# GD32A72_A74x register map
File version: 1.0
CPU: CM7 r2p1, little endian, MPU, FPU, DSP, 4 interrupt priority bits
Registers are 32-bit, read-write, reset 0x0 unless marked. A register's access mark holds for its fields unless they carry their own. Offsets are from the block's base; [hi:lo] are bit positions; 'fields as' and 'values as' point back to an identical list.

## ENET_MTL
Base 0x4000AC00
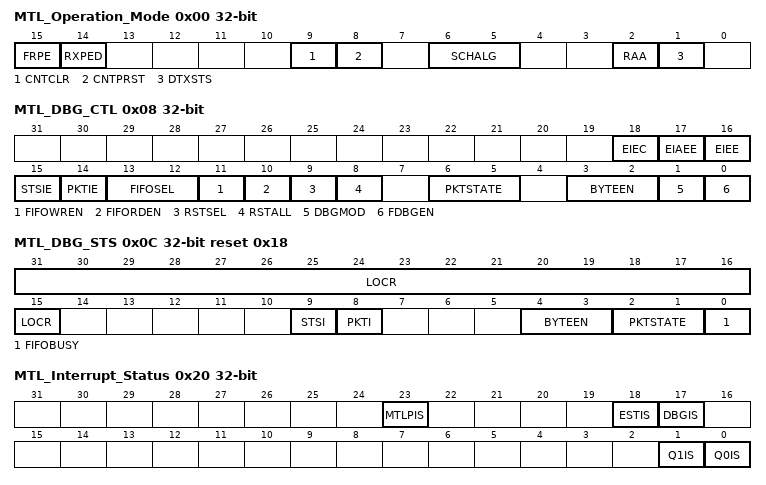
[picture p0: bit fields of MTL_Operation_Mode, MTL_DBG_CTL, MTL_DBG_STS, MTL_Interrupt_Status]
0x00 MTL_Operation_Mode
  [15] FRPE — Flexible Receive Parser Enable
    0=DISABLE (Disabled); 1=ENABLE (Enabled)
  [14] RXPED — RxParser Software Error/Incomplete Parsing Packet Drop Enable
    0=DISABLE (Not reset); 1=ENABLE (Reset)
  [9] CNTCLR — Counters Reset
    0=DISABLE (Not reset); 1=ENABLE (Reset)
  [8] CNTPRST — Counters Preset
    0=DISABLE (Disabled); 1=ENABLE (Enabled)
  [6:5] SCHALG — Transmit Scheduling Algorithm
    0=WRR (WRR algorithm); 1=WFQ (WFQ algorithm when DCB feature selected; otherwise, reserved); 2=DWRR (DWRR algorithm when DCB feature selected; otherwise, reserved); 3=SP (Strict priority algorithm)
  [2] RAA — Receive Arbitration Algorithm
    0=SP (Strict priority (SP)); 1=WSP (Weighted strict priority (WSP))
  [1] DTXSTS — Drop Transmit Status
    0=DISABLE (Disabled); 1=ENABLE (Enabled)
0x08 MTL_DBG_CTL — MTL Debug Control
  [18] EIEC — ECC Inject Error Control for Tx, Rx memories
  [17] EIAEE — ECC Inject Address Error for Tx, Rx memories
  [16] EIEE — ECC Inject Error Enable
    0=DISABLE (Disabled); 1=ENABLE (Enabled)
  [15] STSIE — Transmit Status Available Interrupt Status Enable
    0=DISABLE (Disabled); 1=ENABLE (Enabled)
  [14] PKTIE — Receive Packet Available Interrupt Status Enable
    0=DISABLE (Disabled); 1=ENABLE (Enabled)
  [13:12] FIFOSEL — FIFO Selected for Access
    0=TXFIFO (Transmit FIFO); 1=TXSTSFIFO (Transmit status FIFO (only read access when SLVMOD is set)); 2=TSOFIFO (TSO FIFO (cannot be accessed when SLVMOD is set)); 3=RXFIFO (Receive FIFO)
  [11] FIFOWREN — FIFO Write Enable
    0=DISABLE (Disabled); 1=ENABLE (Enabled)
  [10] FIFORDEN — FIFO Read Enable
    0=DISABLE (Disabled); 1=ENABLE (Enabled)
  [9] RSTSEL — Reset Pointers Of Selected FIFO
    0=DISABLE (Disabled); 1=ENABLE (Enabled)
  [8] RSTALL — Reset All Pointers
    0=DISABLE (Disabled); 1=ENABLE (Enabled)
  [6:5] PKTSTATE — Encoded Packet State
    0=PKT_DATA (Packet data); 1=CW_NS (Control word/normal status); 2=SOP_LS (SOP data/last status); 3=EOP (EOP data/EOP)
  [3:2] BYTEEN — Byte Enables
    0=B0_VAL (Byte 0 valid); 1=B01_VAL (Byte 0 and byte 1 valid); 2=B012_VAL (Byte 0, byte 1, and byte 2 valid); 3=B0123_VAL (All four bytes valid)
  [1] DBGMOD — Debug Mode Access to FIFO
    0=DISABLE (Disabled); 1=ENABLE (Enabled)
  [0] FDBGEN — FIFO Debug Access Enable
    0=DISABLE (Disabled); 1=ENABLE (Enabled)
0x0C MTL_DBG_STS reset 0x18 — MTL Debug Status
  [31:15] LOCR ro — Remaining Locations In FIFO
  [9] STSI — Transmit Status Available Interrupt Status
    0=INACTIVE (Not detected); 1=ACTIVE (Detected)
  [8] PKTI — Receive Packet Available Interrupt Status
    0=INACTIVE (Not detected); 1=ACTIVE (Detected)
  [4:3] BYTEEN ro — Byte Enables
    values as MTL_DBG_CTL.BYTEEN
  [2:1] PKTSTATE ro — Encoded Packet State
    values as MTL_DBG_CTL.PKTSTATE
  [0] FIFOBUSY ro
    0=INACTIVE (Not detected); 1=ACTIVE (Detected)
0x10 MTL_FIFO_Debug_Data
  [31:0] FDBGDATA — FIFO Debug Data
0x20 MTL_Interrupt_Status ro
  [all] fields
    0=INACTIVE (Not detected); 1=ACTIVE (Detected)
  [23] MTLPIS — MTL Receive Parser Interrupt Status
  [18] ESTIS — EST (TAS- 802.1Qbv) Interrupt Status
  [17] DBGIS — Debug Interrupt Status
  [1] Q1IS — Queue 1 Interrupt Status
  [0] Q0IS — Queue 0 Interrupt Status
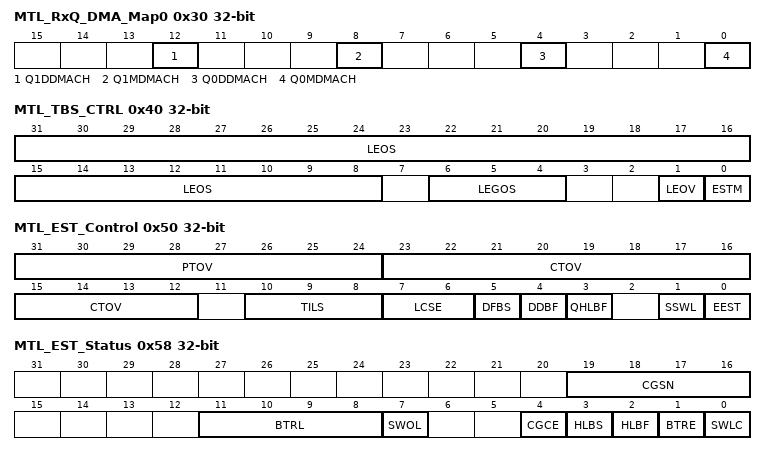
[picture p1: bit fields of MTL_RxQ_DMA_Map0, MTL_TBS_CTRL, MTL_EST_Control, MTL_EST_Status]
0x30 MTL_RxQ_DMA_Map0 — MTL Receive Queue DMA Map 0
  [12] Q1DDMACH — Queue 1 Enabled for DA-based DMA Channel Selection
    0=DISABLE (Disabled); 1=ENABLE (Enabled)
  [8] Q1MDMACH — Queue 1 Mapped to DMA Channel
  [4] Q0DDMACH — Queue 0 Enabled for DA-based DMA Channel Selection
    0=DISABLE; 1=ENABLE
  [0] Q0MDMACH — Queue 0 Mapped to DMA Channel
0x40 MTL_TBS_CTRL — MTL TBS Control
  [31:8] LEOS — Launch Expiry Offset
  [6:4] LEGOS — Launch Expiry GSN Offset
  [1] LEOV — Launch Expiry Offset Valid
    0=INVALID; 1=VALID
  [0] ESTM — EST offset Mode
    0=DISABLE (Disabled); 1=ENABLE (Enabled)
0x50 MTL_EST_Control
  [31:24] PTOV — PTP Time Offset Value
  [23:12] CTOV — Current Time Offset Value
  [10:8] TILS — Time Interval Left Shift Amount
  [7:6] LCSE — Loop Count to Report Scheduling Error
    0=M_4_ITERNS (4 iterations); 1=M_8_ITERNS (8 iterations); 2=M_16_ITERNS (16 iterations); 3=M_32_ITERNS (32 iterations)
  [5] DFBS — Drop Frames Causing Scheduling Error
    0=DONT_DROP (Do not drop frames); 1=DROP (Drop frames)
  [4] DDBF — Do not Drop Frames during Frame Size Error
    0=DROP (Drop frames during frame size error); 1=DONT_DROP (Do not Drop frames during frame size error)
  [3] QHLBF — Quick Assertion of HLBF Error
  [1] SSWL — Switch to Software Owned List
    0=DISABLE (Disabled); 1=ENABLE (Enabled)
  [0] EEST — Enable EST
    0=DISABLE (Disabled); 1=ENABLE (Enabled)
0x54 MTL_EST_Ext_Control — MTL EST extend control register
  [5:0] OVHD — Overhead Bytes Value
0x58 MTL_EST_Status
  [19:16] CGSN ro — Current GCL Slot Number Indicates the slot number of the GCL list
  [11:8] BTRL ro — BTR Error Loop Count Provides the minimum count (N) for which the equation Current Time =< New BTR + (N * New Cycle Time) becomes true
  [7] SWOL ro — S/W owned list When '0' indicates Gate control list number "0" is owned by software and when "1" indicates the Gate Control list "1" is owned by the software
    0=INACTIVE (Gate control list number "0" is owned by software); 1=ACTIVE (Gate control list number "1" is owned by software)
  [4] CGCE — Constant Gate Control Error This error occurs when the list length (LLR) is 1 and the Cycle Time (CTR) is less than or equal to the programmed Time Interval (TI) value after the optional Left Shifting
    0=INACTIVE (Constant Gate Control Error not detected); 1=ACTIVE (Constant Gate Control Error detected)
  [3] HLBS ro — Head-Of-Line Blocking due to Scheduling Set when the frame is not able to win arbitration and get scheduled even after 4 iterations of the GCL
    0=INACTIVE (Head-Of-Line Blocking due to Scheduling not detected); 1=ACTIVE (Head-Of-Line Blocking due to Scheduling detected)
  [2] HLBF ro — Head-Of-Line Blocking due to Frame Size Set when HOL Blocking is noticed on one or more Queues as a result of none of the Time Intervals of gate open in the GCL being greater than or equal to the duration needed for frame size (or frame fragment size when preemption is enabled) transmission
    0=INACTIVE (Head-Of-Line Blocking due to Frame Size not detected); 1=ACTIVE (Head-Of-Line Blocking due to Frame Size detected)
  [1] BTRE — BTR Error
    0=INACTIVE (BTR Error not detected); 1=ACTIVE (BTR Error detected)
  [0] SWLC — Switch to Software Owned List Complete
    0=INACTIVE (Not detected); 1=ACTIVE (Detected)
0x60 MTL_EST_Sch_Error — MTL EST Scheduling Error
  [1:0] SEQN — Schedule Error Queue Number
0x64 MTL_EST_Frm_Size_Error — MTL EST Frame Size Error
  [1:0] FEQN — Frame Size Error Queue Number
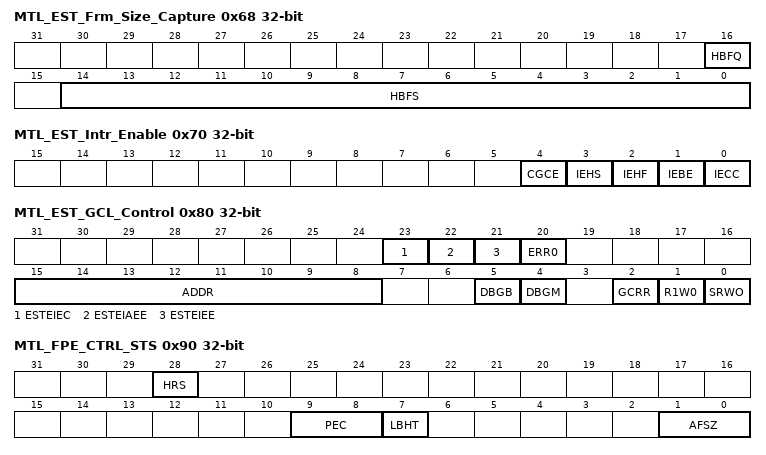
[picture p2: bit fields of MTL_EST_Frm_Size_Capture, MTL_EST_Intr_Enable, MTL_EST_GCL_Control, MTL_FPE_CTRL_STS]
0x68 MTL_EST_Frm_Size_Capture ro — MTL EST Frame Size Capture
  [16] HBFQ — Queue Number of HLBF
  [14:0] HBFS — Frame Size of HLBF
0x70 MTL_EST_Intr_Enable — MTL EST Interrupt Enable
  [all] fields
    0=DISABLE (Disabled); 1=ENABLE (Enabled)
  [4] CGCE — Interrupt Enable for CGCE
  [3] IEHS — Interrupt Enable for HLBS
  [2] IEHF — Interrupt Enable for HLBF
  [1] IEBE — Interrupt Enable for BTR Error
  [0] IECC — Interrupt Enable for Switch List
0x80 MTL_EST_GCL_Control
  [23] ESTEIEC — ECC Inject Error Control for EST Memory
  [22] ESTEIAEE — EST ECC Inject Address Error Enable
  [21] ESTEIEE — EST ECC Inject Error Enable
    0=DISABLE (Disabled); 1=ENABLE (Enabled)
  [20] ERR0 — If this field is 1, it indicates that when the software writes to GCL the last write operation was aborted and when MTL_EST_Control[SSWL] is 1, GCL registers are prohibited
    0=DISABLE (ERR0 is disabled); 1=ENABLE (ERR1 is enabled)
  [15:8] ADDR — Gate Control List Address: (GCLA when GCRR is "0")
  [5] DBGB — Debug Mode Bank Select
    0=BANK0 (Directed to bank 0); 1=BANK1 (Directed to bank 1)
  [4] DBGM — Debug Mode
    0=DISABLE (Disabled); 1=ENABLE (Enabled)
  [2] GCRR — Gate Control Related Registers
    0=DISABLE (Disabled); 1=ENABLE (Enabled)
  [1] R1W0 — Read '1', Write '0'
    0=WRITE (Write operation); 1=READ (Read operation)
  [0] SRWO — Start Read/Write Operation
    0=DISABLE (Disabled); 1=ENABLE (Enabled)
0x84 MTL_EST_GCL_Data
  [31:0] GCD — Gate Control Data
0x90 MTL_FPE_CTRL_STS — MTL FPE Control Status
  [28] HRS ro — Hold/Release Status
    0=SET_REL (Release state); 1=SET_HOLD (Hold state)
  [9:8] PEC — Preemption Classification
  [7] LBHT — Level Based Hold Transition
  [1:0] AFSZ — Additional Fragment Size
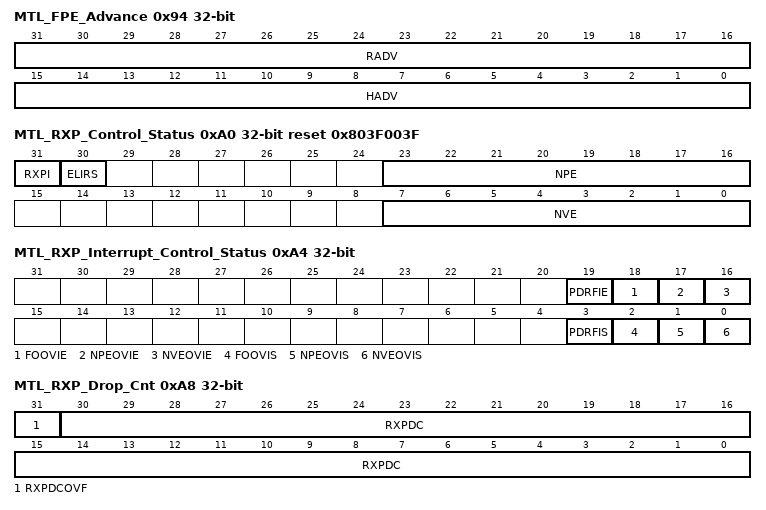
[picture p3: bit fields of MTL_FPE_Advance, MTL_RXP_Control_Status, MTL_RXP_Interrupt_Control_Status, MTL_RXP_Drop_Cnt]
0x94 MTL_FPE_Advance
  [31:16] RADV — Release Advance
  [15:0] HADV — Hold Advance
0xA0 MTL_RXP_Control_Status reset 0x803F003F — MTL Rx Parser Control Status
  [31] RXPI ro — RX Parser in Idle State
    0=INACTIVE (Not in Idle state); 1=ACTIVE (Idle state)
  [30] ELIRS — Enable Last Instruction in RX Status
  [23:16] NPE — Number of parsable entries in the Instruction table
  [7:0] NVE — Number Of Valid Entry Address Or Index In The Instruction Table
0xA4 MTL_RXP_Interrupt_Control_Status — MTL Rx Parser Interrupt Control Status
  [19] PDRFIE — Packet Drop due to RF Interrupt Enable
    0=DISABLE (Disabled); 1=ENABLE (Enabled)
  [18] FOOVIE — Frame Offset Overflow Interrupt Enable
    0=DISABLE (Disabled); 1=ENABLE (Enabled)
  [17] NPEOVIE — Number of Parsable Entries Overflow Interrupt Enable
    0=DISABLE; 1=ENABLE
  [16] NVEOVIE — Number of Valid Entries Overflow Interrupt Enable
    0=DISABLE; 1=ENABLE
  [3] PDRFIS — Packet Dropped due to RF Interrupt Status
    0=INACTIVE (Not detected); 1=ACTIVE (Detected)
  [2] FOOVIS — Frame Offset Overflow Interrupt Status
    0=INACTIVE (Not detected); 1=ACTIVE (Detected)
  [1] NPEOVIS — Number of Parsable Entries Overflow Interrupt Status
    0=INACTIVE (Not detected); 1=ACTIVE (Detected)
  [0] NVEOVIS — Number of Valid Entry Address/Index Overflow Interrupt Status
    0=INACTIVE (Not detected); 1=ACTIVE (Detected)
0xA8 MTL_RXP_Drop_Cnt ro — MTL Rx Parser Drop Count
  [31] RXPDCOVF — Rx Parser Drop Counter Overflow Bit
    0=INACTIVE (Not occurred); 1=ACTIVE (Occurred)
  [30:0] RXPDC — Rx Parser Drop Count
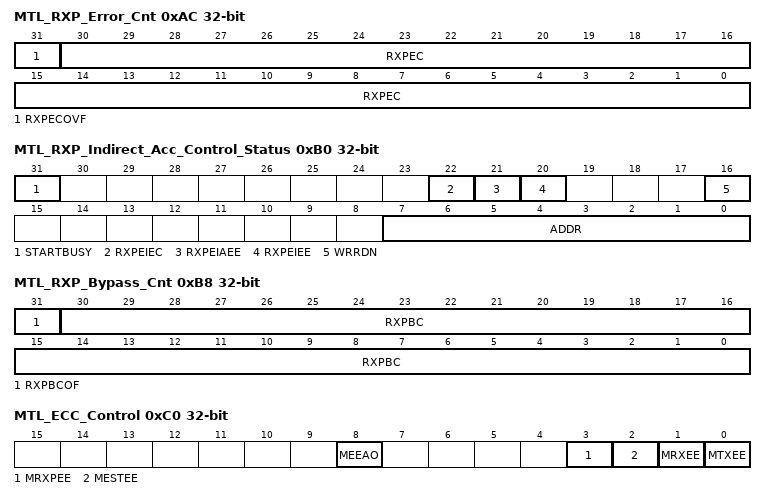
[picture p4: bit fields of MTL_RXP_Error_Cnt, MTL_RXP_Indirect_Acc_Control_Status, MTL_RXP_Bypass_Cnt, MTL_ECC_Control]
0xAC MTL_RXP_Error_Cnt ro — MTL Rx Parser Error Count
  [31] RXPECOVF — Rx Parser Error Counter Overflow Bit
    0=INACTIVE (Not occurred); 1=ACTIVE (Occurred)
  [30:0] RXPEC — Rx Parser Error Count
0xB0 MTL_RXP_Indirect_Acc_Control_Status — MTL Rx Parser Indirect Access Control Status
  [31] STARTBUSY — FRP Instruction Table Access Busy
    0=INACTIVE (hardware not busy); 1=ACTIVE (hardware is busy (Read/Write operation from/to the Rx Parser Memory))
  [22] RXPEIEC — ECC Inject Error Control for Rx Parser Memory
  [21] RXPEIAEE — ECC Inject Address Error Enable for Rx Parser Memory
  [20] RXPEIEE — ECC Inject Error Enable for Rx Parser Memory
    0=DISABLE (Disabled); 1=ENABLE (Enabled)
  [16] WRRDN — Read Write Control
    0=READ (Read operation to the receive parser memory); 1=WRITE (Write operation to the receive parser memory)
  [7:0] ADDR — FRP Instruction Table Offset Address
0xB4 MTL_RXP_Indirect_Acc_Data ro — MTL Rx Parser Indirect Access Data
  [31:0] DATA — FRP Instruction Table Write/Read Data
0xB8 MTL_RXP_Bypass_Cnt ro — MTL Rx parser bypass counter register
  [31] RXPBCOF — Rx Parser Bypass Counter Overflow Bit
  [30:0] RXPBC — Rx Parser Bypass count
0xC0 MTL_ECC_Control
  [8] MEEAO — MTL ECC Error Address Status Over-ride
    0=DISABLE; 1=ENABLE
  [3] MRXPEE — MTL Rx Parser ECC Enable
    0=DISABLE (Disabled); 1=ENABLE (Enabled)
  [2] MESTEE — MTL EST ECC Enable
    0=DISABLE (Disabled); 1=ENABLE (Enabled)
  [1] MRXEE — MTL Rx FIFO ECC Enable
    0=DISABLE (Disabled); 1=ENABLE (Enabled)
  [0] MTXEE — MTL Tx FIFO ECC Enable
    0=DISABLE (Disabled); 1=ENABLE (Enabled)
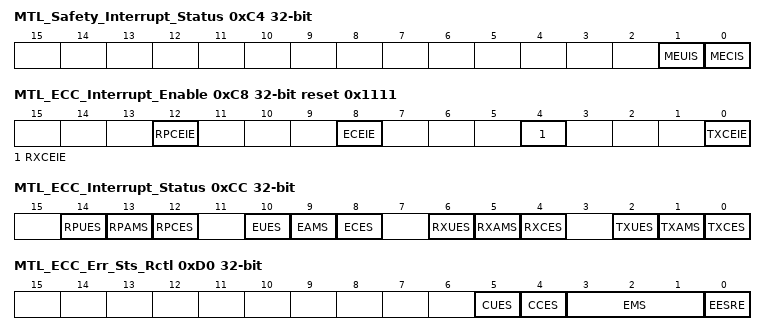
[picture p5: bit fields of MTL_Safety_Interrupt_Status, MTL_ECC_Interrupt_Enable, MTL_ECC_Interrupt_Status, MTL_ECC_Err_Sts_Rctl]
0xC4 MTL_Safety_Interrupt_Status ro — MTL Safety Interript Status
  [1] MEUIS — MTL ECC Uncorrectable Error Interrupt Status
    0=INACTIVE (Not detected); 1=ACTIVE (Detected)
  [0] MECIS — MTL ECC Correctable Error Interrupt Status
    0=INACTIVE (MTL ECC Correctable error Interrupt Status not detected); 1=ACTIVE (MTL ECC Correctable error Interrupt Status detected)
0xC8 MTL_ECC_Interrupt_Enable reset 0x1111
  [all] fields
    0=DISABLE (Disabled); 1=ENABLE (Enabled)
  [12] RPCEIE — Rx Parser Memory Correctable Error Interrupt Enable
  [8] ECEIE — EST Memory Correctable Error Interrupt Enable
  [4] RXCEIE — Rx Memory Correctable Error Interrupt Enable
  [0] TXCEIE — Tx Memory Correctable Error Interrupt Enable
0xCC MTL_ECC_Interrupt_Status
  [all] fields
    0=INACTIVE (Not detected); 1=ACTIVE (Detected)
  [14] RPUES — Rx Parser Memory Uncorrectable Error Status
  [13] RPAMS — MTL Rx Parser Memory Address Mismatch Status
  [12] RPCES — MTL Rx Parser Memory Correctable Error Status
  [10] EUES — MTL EST Memory Uncorrectable Error Status
  [9] EAMS — MTL EST Memory Address Mismatch Status
  [8] ECES — MTL EST Memory Correctable Error Status
  [6] RXUES — MTL Rx Memory Uncorrectable Error Status
  [5] RXAMS — MTL Rx Memory Address Mismatch Status
  [4] RXCES — MTL Rx memory Correctable Error Status
  [2] TXUES — MTL Tx Memory Uncorrectable Error Status
  [1] TXAMS — MTL Tx Memory Address Mismatch Status
  [0] TXCES — MTL Tx Memory Correctable Error Status
0xD0 MTL_ECC_Err_Sts_Rctl — MTL ECC Error Status
  [5] CUES — Clear Uncorrectable Error Status
    0=INACTIVE (Not detected); 1=ACTIVE (Detected)
  [4] CCES — Clear Correctable Error Status
    0=INACTIVE (Not detected); 1=ACTIVE (Detected)
  [3:1] EMS — MTL ECC Memory Selection
    0=TX_MEM (MTL Tx memory); 1=RX_MEM (MTL Rx memory); 2=EST_MEM (MTL EST memory); 3=RXP_MEM (MTL Rx Parser memory); 4=TSO_MEM (DMA TSO memory)
  [0] EESRE — MTL ECC Error Status Read Enable
    0=DISABLE (Disabled); 1=ENABLE (Enabled)
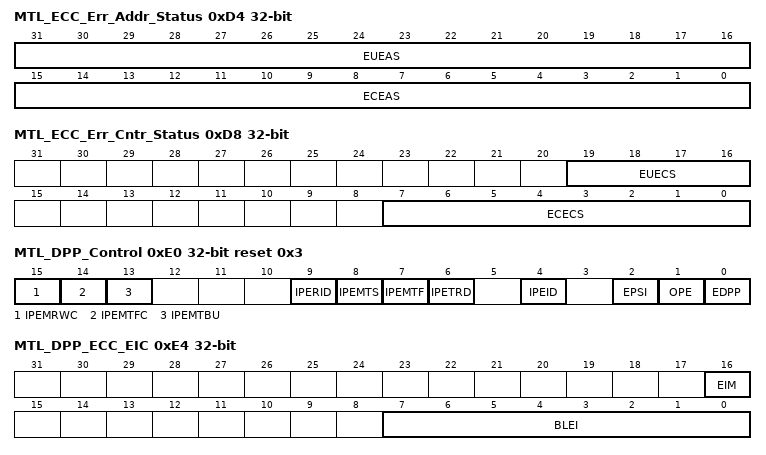
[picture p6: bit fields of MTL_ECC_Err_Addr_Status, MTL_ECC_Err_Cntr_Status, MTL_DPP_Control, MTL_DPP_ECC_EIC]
0xD4 MTL_ECC_Err_Addr_Status ro — MTL ECC Error Adress Status
  [31:16] EUEAS — MTL ECC Uncorrectable Error Address Status
  [15:0] ECEAS — MTL ECC Correctable Error Address Status
0xD8 MTL_ECC_Err_Cntr_Status ro — MTL ECC Error Control Status
  [19:16] EUECS — MTL ECC Uncorrectable Error Counter Status Based on the EMS field of MTL_ECC_Err_Cntr_Rctl register, this field holds the respective memory's uncorrectable error count value
  [7:0] ECECS — MTL ECC Correctable Error Counter Status Based on the EMS field of MTL_ECC_Err_Cntr_Rctl register, this field holds the respective memory's correctable error count value
0xE0 MTL_DPP_Control reset 0x3
  [15] IPEMRWC — Insert Parity error in MTL RWC data Parity Checker
    0=DISABLE (Disabled); 1=ENABLE (Enabled)
  [14] IPEMTFC — Insert Parity error in MAC TFC data Parity Checker
    0=DISABLE (Disabled); 1=ENABLE (Enabled)
  [13] IPEMTBU — Insert Parity error in MAC TBU data Parity Checker
    0=DISABLE (Disabled); 1=ENABLE (Enabled)
  [9] IPERID — Insert Parity Error in RX Interface Data Parity Checker
    0=DISABLE (Disabled); 1=ENABLE (Enabled)
  [8] IPEMTS — Insert Parity Error in MTL Tx Status FIFO Parity Checker
    0=DISABLE (Disabled); 1=ENABLE (Enabled)
  [7] IPEMTF — Insert Parity Error in MTL Tx FIFO write data Parity Checker
    0=DISABLE (Disabled); 1=ENABLE (Enabled)
  [6] IPETRD — Insert Parity Error in DMA Tx/Rx Descriptor Parity Checker
    0=DISABLE (Disabled); 1=ENABLE (Enabled)
  [4] IPEID — Insert Parity Error in Interface Data Parity Generator
    0=DISABLE (Disabled); 1=ENABLE (Enabled)
  [2] EPSI ro — Enable Parity on Slave Interface port
  [1] OPE ro — Odd Parity Enable
    0=DISABLE (Disabled); 1=ENABLE (Enabled)
  [0] EDPP — Enable Data path Parity Protection
    0=DISABLE; 1=ENABLE
0xE4 MTL_DPP_ECC_EIC — MTL ECC/DPP error injection register
  [16] EIM — Error Injection Mode
  [7:0] BLEI — Bit Location of error injection
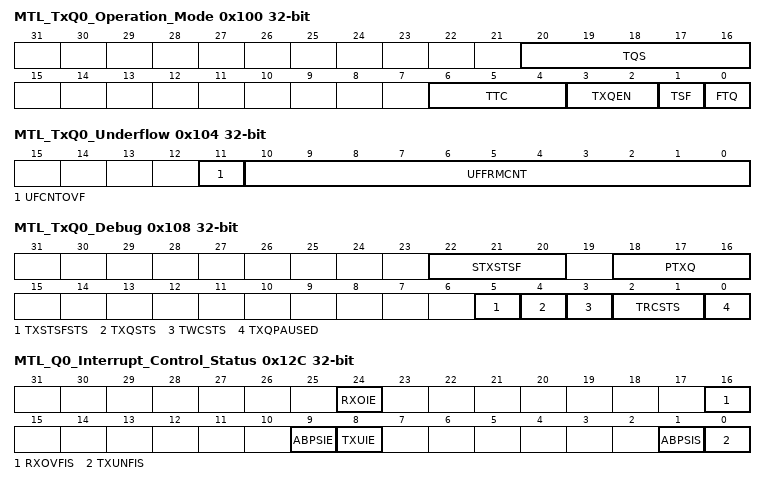
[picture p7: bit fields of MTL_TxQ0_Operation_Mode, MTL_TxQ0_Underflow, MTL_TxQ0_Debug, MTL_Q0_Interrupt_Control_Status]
0x100 MTL_TxQ0_Operation_Mode — MTL Tx Queue 0 Operation Mode
  [20:16] TQS — Transmit Queue Size
  [6:4] TTC — Transmit Threshold Control
    0=M_32BYTES (32); 1=M_64BYTES (64); 2=M_96BYTES (96); 3=M_128BYTES (128); 4=M_192BYTES (192); 5=M_256BYTES (256); 6=M_384BYTES (384); 7=M_512BYTES (512)
  [3:2] TXQEN — Transmit Queue Enable
    0=DISABLE (Not enabled); 1=EN_IF_AV (Enable in AV mode (Reserved in non-AV)); 2=ENABLE (Enabled)
  [1] TSF — Transmit Store and Forward
    0=DISABLE (Disabled); 1=ENABLE (Enabled)
  [0] FTQ — Flush Transmit Queue
    0=DISABLE (Disabled); 1=ENABLE (Enabled)
0x104 MTL_TxQ0_Underflow ro — MTL Tx Queue 0 Underflow
  [11] UFCNTOVF — Overflow Bit for Underflow Packet Counter
    0=INACTIVE (Not detected); 1=ACTIVE (Detected)
  [10:0] UFFRMCNT — Underflow Packet Counter
0x108 MTL_TxQ0_Debug ro — MTL Tx Queue 0 Debug
  [22:20] STXSTSF — Number of Status Words in Tx Status FIFO of Queue
  [18:16] PTXQ — Number of Packets in the Transmit Queue
  [5] TXSTSFSTS — MTL Tx Status FIFO Full Status
    0=INACTIVE (Not detected); 1=ACTIVE (Detected)
  [4] TXQSTS — MTL Tx Queue Not Empty Status
    0=INACTIVE (Not detected); 1=ACTIVE (Detected)
  [3] TWCSTS — MTL Tx Queue Write Controller Status
    0=INACTIVE (Not detected); 1=ACTIVE (Detected)
  [2:1] TRCSTS — MTL Tx Queue Read Controller Status
    0=IDLE (Idle state); 1=READ (Read state (transferring data to the MAC transmitter)); 2=WAIT (Waiting for pending transit status from the MAC transmitter); 3=FLUSH (Flushing the transit queue because of the packet abort request from the MAC)
  [0] TXQPAUSED — Transmit Queue in Pause
    0=INACTIVE (Not detected); 1=ACTIVE (Detected)
0x114 MTL_TxQ0_ETS_Status ro — MTL Tx Queue 0 ETS Status
  [23:0] ABS — Average Bits per Slot
0x118 MTL_TxQ0_Quantum_Weight — MTL Tx Queue Quantum Weight
  [20:0] ISCQW — Quantum or Weights
0x12C MTL_Q0_Interrupt_Control_Status — MTL Queue 0 Interrupt Control Status
  [24] RXOIE — Receive Queue Overflow Interrupt Enable
    0=DISABLE (Disabled); 1=ENABLE (Enabled)
  [16] RXOVFIS — Receive Queue Overflow Interrupt Status
    0=INACTIVE (Not detected); 1=ACTIVE (Detected)
  [9] ABPSIE — Average Bits Per Slot Interrupt Enable
    0=DISABLE (Disabled); 1=ENABLE (Enabled)
  [8] TXUIE — Transmit Queue Underflow Interrupt Enable
    0=DISABLE (Disabled); 1=ENABLE (Enabled)
  [1] ABPSIS — Average Bits Per Slot Interrupt Status
    0=INACTIVE (Not detected); 1=ACTIVE (Detected)
  [0] TXUNFIS — Transmit Queue Underflow Interrupt Status
    0=INACTIVE (Not detected); 1=ACTIVE (Detected)
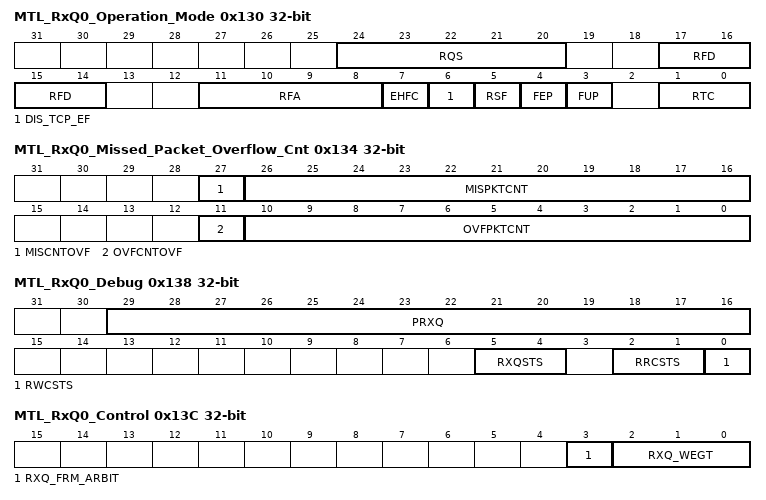
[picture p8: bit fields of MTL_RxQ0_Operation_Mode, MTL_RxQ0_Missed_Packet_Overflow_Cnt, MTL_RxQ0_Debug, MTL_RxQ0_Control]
0x130 MTL_RxQ0_Operation_Mode — MTL Rx Queue 0 Operation Mode
  [24:20] RQS — Receive Queue Size
  [17:14] RFD — Threshold for Deactivating Flow Control (in half-duplex and full-duplex modes)
  [11:8] RFA — Threshold for Activating Flow Control (in half-duplex and full-duplex)
  [7] EHFC — Enable Hardware Flow Control
    0=DISABLE; 1=ENABLE
  [6] DIS_TCP_EF — Disable Dropping of TCP/IP Checksum Error Packets
    0=ENABLE; 1=DISABLE
  [5] RSF — Receive Queue Store and Forward
    0=DISABLE (Disabled); 1=ENABLE (Enabled)
  [4] FEP — Forward Error Packets
    0=DISABLE (Disabled); 1=ENABLE (Enabled)
  [3] FUP — Forward Undersized Good Packets
    0=DISABLE (Disabled); 1=ENABLE (Enabled)
  [1:0] RTC — Receive Queue Threshold Control
    0=M_64BYTE (64); 1=M_32BYTE (32); 2=M_96BYTE (96); 3=M_128BYTE (128)
0x134 MTL_RxQ0_Missed_Packet_Overflow_Cnt ro — MTL Rx Queue Missed Packet Overflow Count
  [27] MISCNTOVF — Missed Packet Counter Overflow Bit
    0=INACTIVE (Not detected); 1=ACTIVE (Detected)
  [26:16] MISPKTCNT — Missed Packet Counter
  [11] OVFCNTOVF — Overflow Counter Overflow Bit
    0=INACTIVE (Not detected); 1=ACTIVE (Detected)
  [10:0] OVFPKTCNT — Overflow Packet Counter
0x138 MTL_RxQ0_Debug ro — MTL Rx Queue 0 Debug
  [29:16] PRXQ — Number of Packets in Receive Queue
  [5:4] RXQSTS — MTL Rx Queue Fill-Level Status
    0=EMPTY (Rx Queue empty); 1=BLW_THR (Rx Queue fill-level below flow-control deactivate threshold); 2=ABV_THR (Rx Queue fill-level above flow-control activate threshold); 3=FULL (Rx Queue full)
  [2:1] RRCSTS — MTL Rx Queue Read Controller State
    0=IDLE (Idle state); 1=READ_DATA (Reading packet data); 2=READ_STS (Reading packet status (or timestamp)); 3=FLUSH (Flushing the packet data and status)
  [0] RWCSTS — MTL Rx Queue Write Controller Active Status
    0=INACTIVE (Not detected); 1=ACTIVE (Detected)
0x13C MTL_RxQ0_Control — MTL Rx Queue 0 Control 0
  [3] RXQ_FRM_ARBIT — Receive Queue Packet Arbitration
    0=DISABLE (Disabled); 1=ENABLE (Enabled)
  [2:0] RXQ_WEGT — Receive Queue Weight
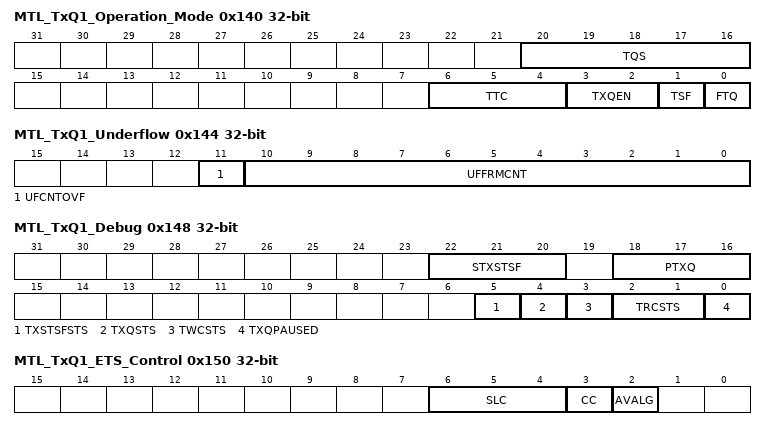
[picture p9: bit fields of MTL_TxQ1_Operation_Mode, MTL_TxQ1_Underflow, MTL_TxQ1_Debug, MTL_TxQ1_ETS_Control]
0x140 MTL_TxQ1_Operation_Mode — MTL Tx Queue 1 Operation Mode
  [20:16] TQS — Transmit Queue Size
  [6:4] TTC — Transmit Threshold Control
    values as MTL_TxQ0_Operation_Mode.TTC
  [3:2] TXQEN — Transmit Queue Enable
    values as MTL_TxQ0_Operation_Mode.TXQEN
  [1] TSF — Transmit Store and Forward
    0=DISABLE (Transmit Store and Forward is disabled); 1=ENABLE (Transmit Store and Forward is enabled)
  [0] FTQ — Flush Transmit Queue
    0=DISABLE (Disabled); 1=ENABLE (Enabled)
0x144 MTL_TxQ1_Underflow ro — MTL Tx Queue 1 Underflow
  fields as MTL_TxQ0_Underflow
0x148 MTL_TxQ1_Debug ro — MTL Tx Queue 1 Debug
  fields as MTL_TxQ0_Debug
0x150 MTL_TxQ1_ETS_Control — MTL Tx Queue 1 ETS Control
  [6:4] SLC — Slot Count
    0=M_1_SLOT (1 slot); 1=M_2_SLOT (2 slots); 2=M_4_SLOT (4 slots); 3=M_8_SLOT (8 slots); 4=M_16_SLOT (16 slots)
  [3] CC — Credit Control
    0=DISABLE (Disabled); 1=ENABLE (Enabled)
  [2] AVALG — AV Algorithm
    0=DISABLE (Disabled); 1=ENABLE (Enabled)
0x154 MTL_TxQ1_ETS_Status ro — MTL Tx Queue 1 ETS Status
  [23:0] ABS — Average Bits per Slot
0x158 MTL_TxQ1_Quantum_Weight — MTL Tx Queue 1 Quantum Weight
  [20:0] ISCQW — idleSlopeCredit, Quantum or Weights
0x15C MTL_TxQ1_SendSlopeCredit — MTL Tx Queue 1 Sendslope Credit
  [13:0] SSC — sendSlopeCredit Value
0x160 MTL_TxQ1_HiCredit — MTL Tx Queue 1 HiCredit
  [28:0] HC — hiCredit Value
0x164 MTL_TxQ1_LoCredit — MTL Tx Queue 1 LoCredit
  [28:0] LC — loCredit Value
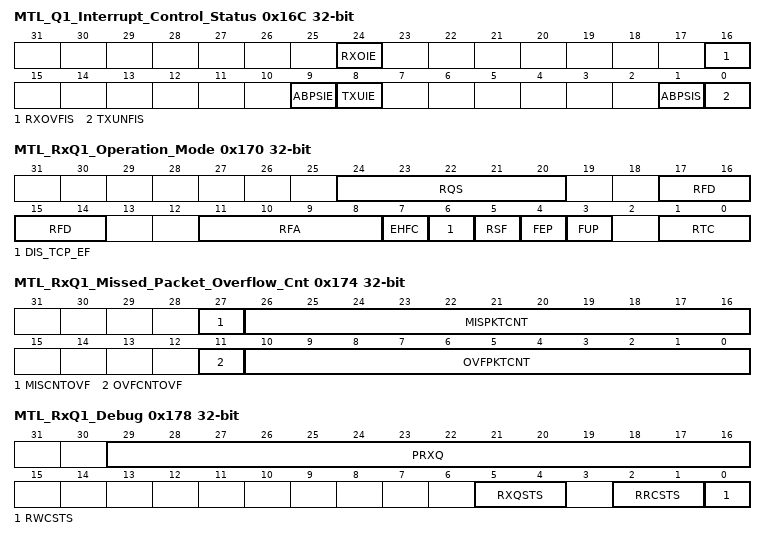
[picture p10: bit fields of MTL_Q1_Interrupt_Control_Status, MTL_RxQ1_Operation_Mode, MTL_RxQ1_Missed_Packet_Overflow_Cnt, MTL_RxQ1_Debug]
0x16C MTL_Q1_Interrupt_Control_Status — MTL Queue 1 Interrupt Control Status
  [24] RXOIE — Receive Queue Overflow Interrupt Enable
    0=DISABLE; 1=ENABLE
  [16] RXOVFIS — Receive Queue Overflow Interrupt Status
    0=INACTIVE (Not detected); 1=ACTIVE (Detected)
  [9] ABPSIE — Average Bits Per Slot Interrupt Enable
    0=DISABLE (Disabled); 1=ENABLE (Enabled)
  [8] TXUIE — Transmit Queue Underflow Interrupt Enable
    0=DISABLE (Disabled); 1=ENABLE (Enabled)
  [1] ABPSIS — Average Bits Per Slot Interrupt Status
    0=INACTIVE (Not detected); 1=ACTIVE (Detected)
  [0] TXUNFIS — Transmit Queue Underflow Interrupt Status
    0=INACTIVE (Not detected); 1=ACTIVE (Detected)
0x170 MTL_RxQ1_Operation_Mode — MTL Rx Queue 1 Operation Mode
  [24:20] RQS — Receive Queue Size
  [17:14] RFD — Threshold for Deactivating Flow Control (in half-duplex and full-duplex modes)
  [11:8] RFA — Threshold for Activating Flow Control (in half-duplex and full-duplex
  [7] EHFC — Enable Hardware Flow Control
    0=DISABLE; 1=ENABLE
  [6] DIS_TCP_EF — Disable Dropping of TCP or IP Checksum Error Packets
    0=ENABLE (Enabled); 1=DISABLE (Disabled)
  [5] RSF — Receive Queue Store and Forward
    0=DISABLE (Disabled); 1=ENABLE (Enabled)
  [4] FEP — Forward Error Packets
    0=DISABLE (Disabled); 1=ENABLE (Enabled)
  [3] FUP — Forward Undersized Good Packets
    0=DISABLE (Disabled); 1=ENABLE (Enabled)
  [1:0] RTC — Receive Queue Threshold Control
    values as MTL_RxQ0_Operation_Mode.RTC
0x174 MTL_RxQ1_Missed_Packet_Overflow_Cnt ro — MTL Rx Queue 1 Missed Packet Overflow Counter
  fields as MTL_RxQ0_Missed_Packet_Overflow_Cnt
0x178 MTL_RxQ1_Debug ro — MTL Rx Queue 1 Debug
  fields as MTL_RxQ0_Debug
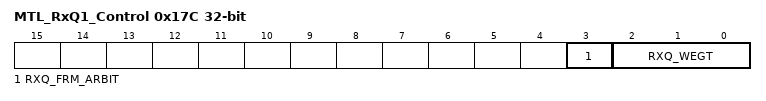
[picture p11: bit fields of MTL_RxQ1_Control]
0x17C MTL_RxQ1_Control — MTL Rx Queue 1 Control
  fields as MTL_RxQ0_Control
